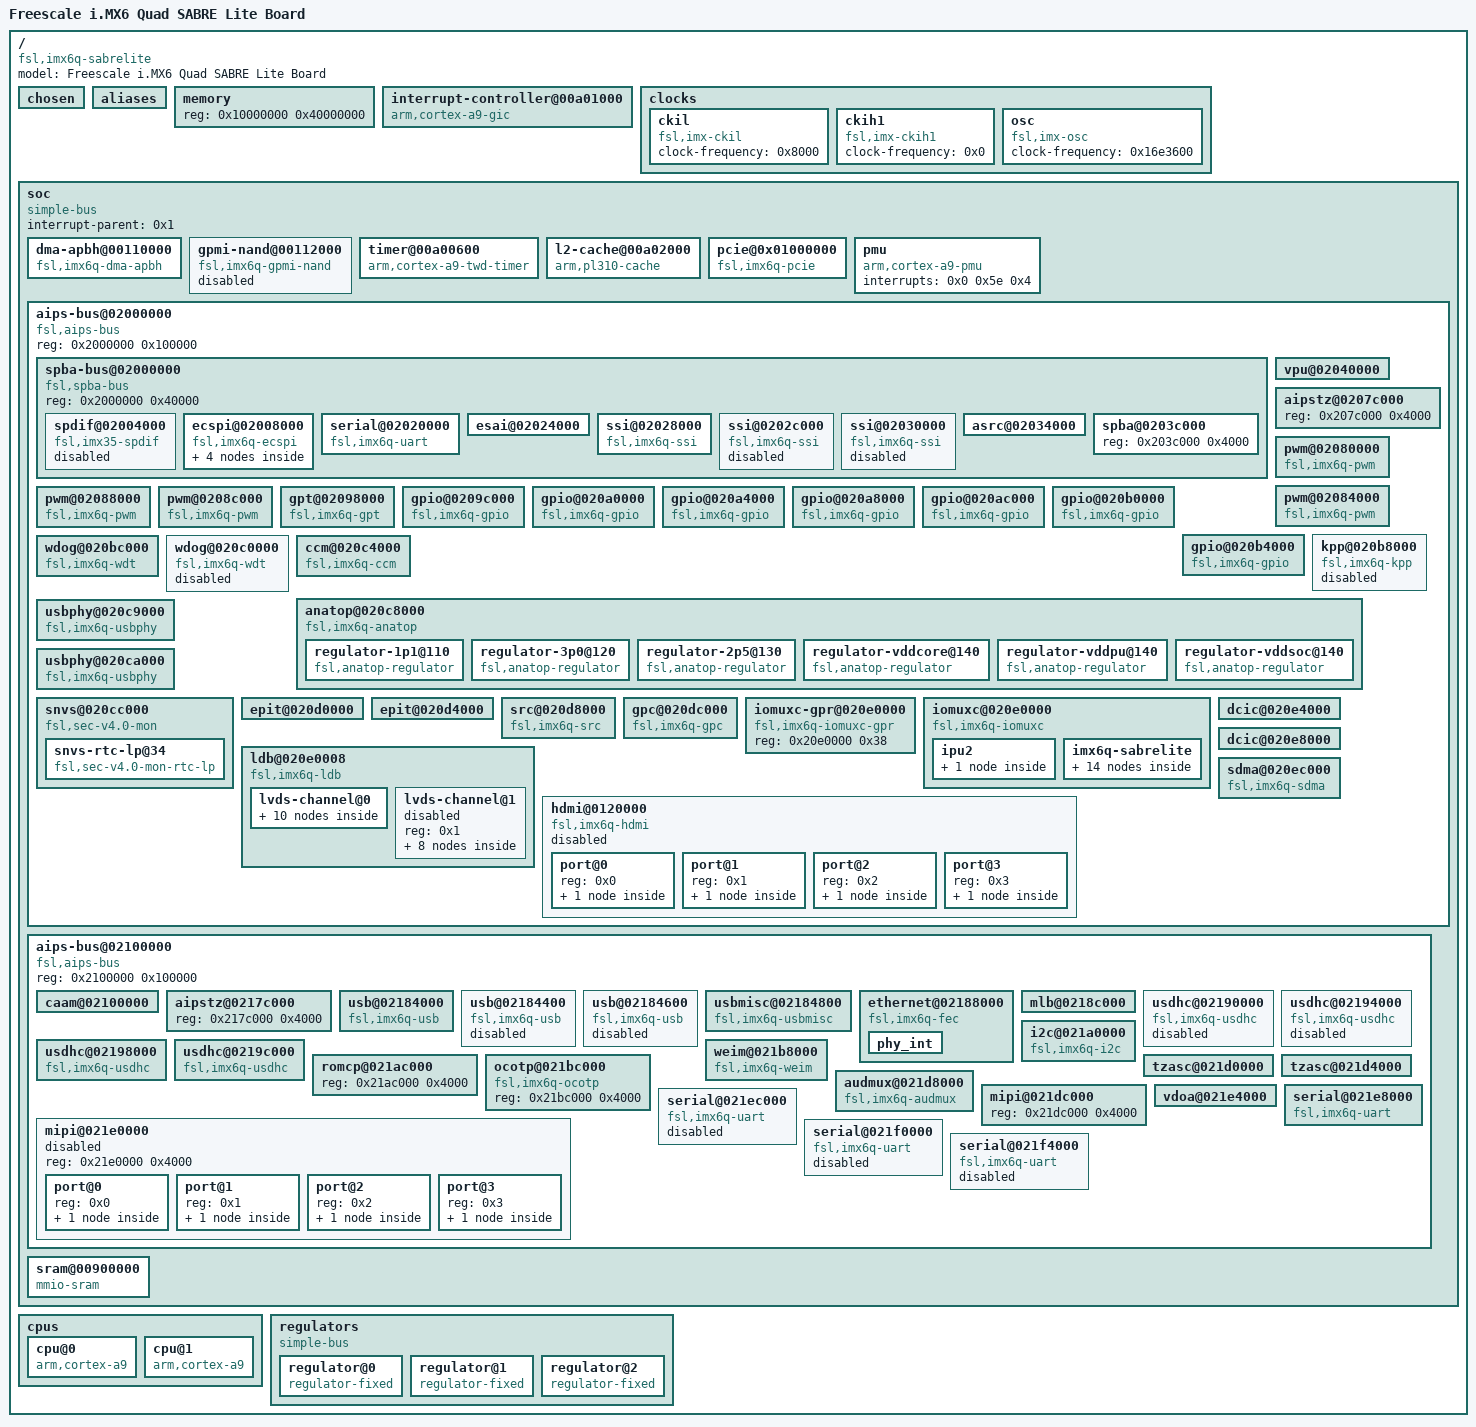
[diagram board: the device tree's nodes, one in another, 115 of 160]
/dts-v1/;

/ {
	#address-cells = <0x1>;
	#size-cells = <0x1>;
	model = "Freescale i.MX6 Quad SABRE Lite Board";
	compatible = "fsl,imx6q-sabrelite", "fsl,imx6q";

	chosen {
		stdout-path = "/soc/aips-bus@02100000/serial@021e8000";
bootargs = "console=ttymxc1,115200 root=/dev/mmcblk0 rw rootwait earlyprintk loglevel=8 mem=862M ip=dhcp video=mxcfb0:dev=ldb,LDB-XGA,if=RGB666";
	};

	aliases {
		ethernet0 = "/soc/aips-bus@02100000/ethernet@02188000";
		can0 = "/soc/aips-bus@02000000/flexcan@02090000";
		can1 = "/soc/aips-bus@02000000/flexcan@02094000";
		gpio0 = "/soc/aips-bus@02000000/gpio@0209c000";
		gpio1 = "/soc/aips-bus@02000000/gpio@020a0000";
		gpio2 = "/soc/aips-bus@02000000/gpio@020a4000";
		gpio3 = "/soc/aips-bus@02000000/gpio@020a8000";
		gpio4 = "/soc/aips-bus@02000000/gpio@020ac000";
		gpio5 = "/soc/aips-bus@02000000/gpio@020b0000";
		gpio6 = "/soc/aips-bus@02000000/gpio@020b4000";
		i2c0 = "/soc/aips-bus@02100000/i2c@021a0000";
		mmc0 = "/soc/aips-bus@02100000/usdhc@02190000";
		mmc1 = "/soc/aips-bus@02100000/usdhc@02194000";
		mmc2 = "/soc/aips-bus@02100000/usdhc@02198000";
		mmc3 = "/soc/aips-bus@02100000/usdhc@0219c000";
		serial0 = "/soc/aips-bus@02000000/spba-bus@02000000/serial@02020000";
		serial1 = "/soc/aips-bus@02100000/serial@021e8000";
		serial2 = "/soc/aips-bus@02100000/serial@021ec000";
		serial3 = "/soc/aips-bus@02100000/serial@021f0000";
		serial4 = "/soc/aips-bus@02100000/serial@021f4000";

		spi0 = "/soc/aips-bus@02000000/spba-bus@02000000/ecspi@02008000";
//		spi1 = "/soc/aips-bus@02000000/spba-bus@02000000/ecspi@0200c000";
//		spi2 = "/soc/aips-bus@02000000/spba-bus@02000000/ecspi@02010000";
//		spi3 = "/soc/aips-bus@02000000/spba-bus@02000000/ecspi@02014000";
//              spi4 = "/soc/aips-bus@02000000/spba-bus@02000000/ecspi@02018000";

		usbphy0 = "/soc/aips-bus@02000000/usbphy@020c9000";
		usbphy1 = "/soc/aips-bus@02000000/usbphy@020ca000";

	};

	memory {
		device_type = "memory";
		reg = <0x10000000 0x40000000>;
	};

	interrupt-controller@00a01000 {
		compatible = "arm,cortex-a9-gic";
		#interrupt-cells = <0x3>;
		interrupt-controller;
		reg = <0xa01000 0x1000 0xa00100 0x100>;
		linux,phandle = <0x1>;
		phandle = <0x1>;
	};

	clocks {
		#address-cells = <0x1>;
		#size-cells = <0x0>;

		ckil {
			compatible = "fsl,imx-ckil", "fixed-clock";
			#clock-cells = <0x0>;
			clock-frequency = <0x8000>;
		};

		ckih1 {
			compatible = "fsl,imx-ckih1", "fixed-clock";
			#clock-cells = <0x0>;
			clock-frequency = <0x0>;
		};

		osc {
			compatible = "fsl,imx-osc", "fixed-clock";
			#clock-cells = <0x0>;
			clock-frequency = <0x16e3600>;
		};
	};

	soc {
		#address-cells = <0x1>;
		#size-cells = <0x1>;
		compatible = "simple-bus";
		interrupt-parent = <0x1>;
		ranges;

		dma-apbh@00110000 {
			compatible = "fsl,imx6q-dma-apbh", "fsl,imx28-dma-apbh";
			reg = <0x110000 0x2000>;
			interrupts = <0x0 0xd 0x4 0x0 0xd 0x4 0x0 0xd 0x4 0x0 0xd 0x4>;
			interrupt-names = "gpmi0", "gpmi1", "gpmi2", "gpmi3";
			#dma-cells = <0x1>;
			dma-channels = <0x4>;
			clocks = <0x2 0x6a>;
			linux,phandle = <0x3>;
			phandle = <0x3>;
		};

		gpmi-nand@00112000 {
			compatible = "fsl,imx6q-gpmi-nand";
			#address-cells = <0x1>;
			#size-cells = <0x1>;
			reg = <0x112000 0x2000 0x114000 0x2000>;
			reg-names = "gpmi-nand", "bch";
			interrupts = <0x0 0xf 0x4>;
			interrupt-names = "bch";
			clocks = <0x2 0x98 0x2 0x99 0x2 0x97 0x2 0x96 0x2 0x95>;
			clock-names = "gpmi_io", "gpmi_apb", "gpmi_bch", "gpmi_bch_apb", "per1_bch";
			dmas = <0x3 0x0>;
			dma-names = "rx-tx";
			status = "disabled";
		};

		timer@00a00600 {
			compatible = "arm,cortex-a9-twd-timer";
			reg = <0xa00600 0x20>;
			interrupts = <0x1 0xd 0xf01>;
			clocks = <0x2 0xf>;
		};

		l2-cache@00a02000 {
			compatible = "arm,pl310-cache";
			reg = <0xa02000 0x1000>;
			interrupts = <0x0 0x5c 0x4>;
			cache-unified;
			cache-level = <0x2>;
			arm,tag-latency = <0x4 0x2 0x3>;
			arm,data-latency = <0x4 0x2 0x3>;
			linux,phandle = <0x3f>;
			phandle = <0x3f>;
		};

		pcie@0x01000000 {
			compatible = "fsl,imx6q-pcie", "snps,dw-pcie";
			reg = <0x1ffc000 0x4000>;
			#address-cells = <0x3>;
			#size-cells = <0x2>;
			device_type = "pci";
			ranges = <0x800 0x0 0x1f00000 0x1f00000 0x0 0x80000 0x81000000 0x0 0x0 0x1f80000 0x0 0x10000 0x82000000 0x0 0x1000000 0x1000000 0x0 0xf00000>;
			num-lanes = <0x1>;
			interrupts = <0x0 0x78 0x4>;
			interrupt-names = "msi";
			#interrupt-cells = <0x1>;
			interrupt-map-mask = <0x0 0x0 0x0 0x7>;
			interrupt-map = <0x0 0x0 0x0 0x1 0x1 0x0 0x7b 0x4 0x0 0x0 0x0 0x2 0x1 0x0 0x7a 0x4 0x0 0x0 0x0 0x3 0x1 0x0 0x79 0x4 0x0 0x0 0x0 0x4 0x1 0x0 0x78 0x4>;
			clocks = <0x2 0x90 0x2 0xce 0x2 0xbd>;
			clock-names = "pcie", "pcie_bus", "pcie_phy";
			status = "okay";
		};

		pmu {
			compatible = "arm,cortex-a9-pmu";
			interrupts = <0x0 0x5e 0x4>;
		};

		aips-bus@02000000 {
			compatible = "fsl,aips-bus", "simple-bus";
			#address-cells = <0x1>;
			#size-cells = <0x1>;
			reg = <0x2000000 0x100000>;
			ranges;

			spba-bus@02000000 {
				compatible = "fsl,spba-bus", "simple-bus";
				#address-cells = <0x1>;
				#size-cells = <0x1>;
				reg = <0x2000000 0x40000>;
				ranges;

				spdif@02004000 {
					compatible = "fsl,imx35-spdif";
					reg = <0x2004000 0x4000>;
					interrupts = <0x0 0x34 0x4>;
					dmas = <0x4 0xe 0x12 0x0 0x4 0xf 0x12 0x0>;
					dma-names = "rx", "tx";
					clocks = <0x2 0xc5 0x2 0x3 0x2 0xc5 0x2 0x0 0x2 0x0 0x2 0x0 0x2 0x0 0x2 0x0 0x2 0x0>;
					clock-names = "core", "rxtx0", "rxtx1", "rxtx2", "rxtx3", "rxtx4", "rxtx5", "rxtx6", "rxtx7";
					status = "disabled";
				};

				ecspi@02008000 {
					#address-cells = <0x1>;
					#size-cells = <0x0>;
					compatible = "fsl,imx6q-ecspi", "fsl,imx51-ecspi";
					reg = <0x2008000 0x4000>;
					interrupts = <0x0 0x1f 0x4>;
					clocks = <0x2 0x70 0x2 0x70>;
					clock-names = "ipg", "per";
					dmas = <0x4 0x3 0x7 0x1 0x4 0x4 0x7 0x2>;
					dma-names = "rx", "tx";
					status = "okay";
					fsl,spi-num-chipselects = <0x4>;
//					pinctrl-names = "default";
//					pinctrl-0 = <0x6>;

				        spidev@0x00 {
   					        compatible = "spidev";
					        spi-max-frequency = <20000000>;
					        reg = <0>;
    					};
				        spidev@0x01 {
   					        compatible = "spidev";
					        spi-max-frequency = <20000000>;
					        reg = <1>;
    					};
				        spidev@0x02 {
   					        compatible = "spidev";
					        spi-max-frequency = <20000000>;
					        reg = <2>;
    					};
				        spidev@0x03 {
   					        compatible = "spidev";
					        spi-max-frequency = <20000000>;
					        reg = <3>;
    					};

				};
/*
				ecspi@0200c000 {
					#address-cells = <0x1>;
					#size-cells = <0x0>;
					compatible = "fsl,imx6q-ecspi", "fsl,imx51-ecspi";
					reg = <0x200c000 0x4000>;
					interrupts = <0x0 0x20 0x4>;
					clocks = <0x2 0x71 0x2 0x71>;
					clock-names = "ipg", "per";
					dmas = <0x4 0x5 0x7 0x1 0x4 0x6 0x7 0x2>;
					dma-names = "rx", "tx";
					status = "disabled";
				};
				ecspi@02010000 {
					#address-cells = <0x1>;
					#size-cells = <0x0>;
					compatible = "fsl,imx6q-ecspi", "fsl,imx51-ecspi";
					reg = <0x2010000 0x4000>;
					interrupts = <0x0 0x21 0x4>;
					clocks = <0x2 0x72 0x2 0x72>;
					clock-names = "ipg", "per";
					dmas = <0x4 0x7 0x7 0x1 0x4 0x8 0x7 0x2>;
					dma-names = "rx", "tx";
					status = "disabled";
				};

				ecspi@02014000 {
					#address-cells = <0x1>;
					#size-cells = <0x0>;
					compatible = "fsl,imx6q-ecspi", "fsl,imx51-ecspi";
					reg = <0x2014000 0x4000>;
					interrupts = <0x0 0x22 0x4>;
					clocks = <0x2 0x73 0x2 0x73>;
					clock-names = "ipg", "per";
					dmas = <0x4 0x9 0x7 0x1 0x4 0xa 0x7 0x2>;
					dma-names = "rx", "tx";
					status = "disabled";
				};
*/
				serial@02020000 {
					compatible = "fsl,imx6q-uart", "fsl,imx21-uart";
					reg = <0x2020000 0x4000>;
					interrupts = <0x0 0x1a 0x4>;
					clocks = <0x2 0xa0 0x2 0xa1>;
					clock-names = "ipg", "per";
					dmas = <0x4 0x19 0x4 0x0 0x4 0x1a 0x4 0x0>;
					dma-names = "rx", "tx";
					status = "okay";
					pinctrl-names = "default";
					pinctrl-0 = <0x7>;
				};

				esai@02024000 {
					reg = <0x2024000 0x4000>;
					interrupts = <0x0 0x33 0x4>;
				};

				ssi@02028000 {
					compatible = "fsl,imx6q-ssi", "fsl,imx51-ssi";
					reg = <0x2028000 0x4000>;
					interrupts = <0x0 0x2e 0x4>;
					clocks = <0x2 0xb2>;
					dmas = <0x4 0x25 0x1 0x0 0x4 0x26 0x1 0x0>;
					dma-names = "rx", "tx";
					fsl,fifo-depth = <0xf>;
					status = "okay";
					linux,phandle = <0x49>;
					phandle = <0x49>;
				};

				ssi@0202c000 {
					compatible = "fsl,imx6q-ssi", "fsl,imx51-ssi";
					reg = <0x202c000 0x4000>;
					interrupts = <0x0 0x2f 0x4>;
					clocks = <0x2 0xb3>;
					dmas = <0x4 0x29 0x1 0x0 0x4 0x2a 0x1 0x0>;
					dma-names = "rx", "tx";
					fsl,fifo-depth = <0xf>;
					status = "disabled";
				};

				ssi@02030000 {
					compatible = "fsl,imx6q-ssi", "fsl,imx51-ssi";
					reg = <0x2030000 0x4000>;
					interrupts = <0x0 0x30 0x4>;
					clocks = <0x2 0xb4>;
					dmas = <0x4 0x2d 0x1 0x0 0x4 0x2e 0x1 0x0>;
					dma-names = "rx", "tx";
					fsl,fifo-depth = <0xf>;
					status = "disabled";
				};

				asrc@02034000 {
					reg = <0x2034000 0x4000>;
					interrupts = <0x0 0x32 0x4>;
				};

				spba@0203c000 {
					reg = <0x203c000 0x4000>;
				};
/*
				ecspi@02018000 {
					#address-cells = <0x1>;
					#size-cells = <0x0>;
					compatible = "fsl,imx6q-ecspi", "fsl,imx51-ecspi";
					reg = <0x2018000 0x4000>;
					interrupts = <0x0 0x23 0x4>;
					clocks = <0x2 0x74 0x2 0x74>;
					clock-names = "ipg", "per";
					status = "disabled";
				};
*/
			};

			vpu@02040000 {
				reg = <0x2040000 0x3c000>;
				interrupts = <0x0 0x3 0x4 0x0 0xc 0x4>;
			};

			aipstz@0207c000 {
				reg = <0x207c000 0x4000>;
			};

			pwm@02080000 {
				#pwm-cells = <0x2>;
				compatible = "fsl,imx6q-pwm", "fsl,imx27-pwm";
				reg = <0x2080000 0x4000>;
				interrupts = <0x0 0x53 0x4>;
				clocks = <0x2 0x3e 0x2 0x91>;
				clock-names = "ipg", "per";
				pinctrl-names = "default";
				pinctrl-0 = <0x8>;
				status = "okay";
				linux,phandle = <0x4b>;
				phandle = <0x4b>;
			};

			pwm@02084000 {
				#pwm-cells = <0x2>;
				compatible = "fsl,imx6q-pwm", "fsl,imx27-pwm";
				reg = <0x2084000 0x4000>;
				interrupts = <0x0 0x54 0x4>;
				clocks = <0x2 0x3e 0x2 0x92>;
				clock-names = "ipg", "per";
			};

			pwm@02088000 {
				#pwm-cells = <0x2>;
				compatible = "fsl,imx6q-pwm", "fsl,imx27-pwm";
				reg = <0x2088000 0x4000>;
				interrupts = <0x0 0x55 0x4>;
				clocks = <0x2 0x3e 0x2 0x93>;
				clock-names = "ipg", "per";
				pinctrl-names = "default";
				pinctrl-0 = <0x9>;
				status = "okay";
			};

			pwm@0208c000 {
				#pwm-cells = <0x2>;
				compatible = "fsl,imx6q-pwm", "fsl,imx27-pwm";
				reg = <0x208c000 0x4000>;
				interrupts = <0x0 0x56 0x4>;
				clocks = <0x2 0x3e 0x2 0x94>;
				clock-names = "ipg", "per";
				pinctrl-names = "default";
				pinctrl-0 = <0xa>;
				status = "okay";
				linux,phandle = <0x4c>;
				phandle = <0x4c>;
			};
/*
			flexcan@02090000 {
				compatible = "fsl,imx6q-flexcan";
				reg = <0x2090000 0x4000>;
				interrupts = <0x0 0x6e 0x4>;
				clocks = <0x2 0x6c 0x2 0x6d>;
				clock-names = "ipg", "per";
				status = "disabled";
			};

			flexcan@02094000 {
				compatible = "fsl,imx6q-flexcan";
				reg = <0x2094000 0x4000>;
				interrupts = <0x0 0x6f 0x4>;
				clocks = <0x2 0x6e 0x2 0x6f>;
				clock-names = "ipg", "per";
				status = "disabled";
			};
*/
			gpt@02098000 {
				compatible = "fsl,imx6q-gpt", "fsl,imx31-gpt";
				reg = <0x2098000 0x4000>;
				interrupts = <0x0 0x37 0x4>;
				clocks = <0x2 0x77 0x2 0x78>;
				clock-names = "ipg", "per";
			};

			gpio@0209c000 {
				compatible = "fsl,imx6q-gpio", "fsl,imx35-gpio";
				reg = <0x209c000 0x4000>;
				interrupts = <0x0 0x42 0x4 0x0 0x43 0x4>;
				gpio-controller;
				#gpio-cells = <0x2>;
				interrupt-controller;
				#interrupt-cells = <0x2>;
				linux,phandle = <0x21>;
				phandle = <0x21>;
			};

			gpio@020a0000 {
				compatible = "fsl,imx6q-gpio", "fsl,imx35-gpio";
				reg = <0x20a0000 0x4000>;
				interrupts = <0x0 0x44 0x4 0x0 0x45 0x4>;
				gpio-controller;
				#gpio-cells = <0x2>;
				interrupt-controller;
				#interrupt-cells = <0x2>;
				linux,phandle = <0x27>;
				phandle = <0x27>;
			};

			gpio@020a4000 {
				compatible = "fsl,imx6q-gpio", "fsl,imx35-gpio";
				reg = <0x20a4000 0x4000>;
				interrupts = <0x0 0x46 0x4 0x0 0x47 0x4>;
				gpio-controller;
				#gpio-cells = <0x2>;
				interrupt-controller;
				#interrupt-cells = <0x2>;
				linux,phandle = <0x5>;
				phandle = <0x5>;
			};

			gpio@020a8000 {
				compatible = "fsl,imx6q-gpio", "fsl,imx35-gpio";
				reg = <0x20a8000 0x4000>;
				interrupts = <0x0 0x48 0x4 0x0 0x49 0x4>;
				gpio-controller;
				#gpio-cells = <0x2>;
				interrupt-controller;
				#interrupt-cells = <0x2>;
				linux,phandle = <0x48>;
				phandle = <0x48>;
			};

			gpio@020ac000 {
				compatible = "fsl,imx6q-gpio", "fsl,imx35-gpio";
				reg = <0x20ac000 0x4000>;
				interrupts = <0x0 0x4a 0x4 0x0 0x4b 0x4>;
				gpio-controller;
				#gpio-cells = <0x2>;
				interrupt-controller;
				#interrupt-cells = <0x2>;
			};

			gpio@020b0000 {
				compatible = "fsl,imx6q-gpio", "fsl,imx35-gpio";
				reg = <0x20b0000 0x4000>;
				interrupts = <0x0 0x4c 0x4 0x0 0x4d 0x4>;
				gpio-controller;
				#gpio-cells = <0x2>;
				interrupt-controller;
				#interrupt-cells = <0x2>;
			};

			gpio@020b4000 {
				compatible = "fsl,imx6q-gpio", "fsl,imx35-gpio";
				reg = <0x20b4000 0x4000>;
				interrupts = <0x0 0x4e 0x4 0x0 0x4f 0x4>;
				gpio-controller;
				#gpio-cells = <0x2>;
				interrupt-controller;
				#interrupt-cells = <0x2>;
				linux,phandle = <0x24>;
				phandle = <0x24>;
			};

			kpp@020b8000 {
				compatible = "fsl,imx6q-kpp", "fsl,imx21-kpp";
				reg = <0x20b8000 0x4000>;
				interrupts = <0x0 0x52 0x4>;
				clocks = <0x2 0x3e>;
				status = "disabled";
			};

			wdog@020bc000 {
				compatible = "fsl,imx6q-wdt", "fsl,imx21-wdt";
				reg = <0x20bc000 0x4000>;
				interrupts = <0x0 0x50 0x4>;
				clocks = <0x2 0x0>;
			};

			wdog@020c0000 {
				compatible = "fsl,imx6q-wdt", "fsl,imx21-wdt";
				reg = <0x20c0000 0x4000>;
				interrupts = <0x0 0x51 0x4>;
				clocks = <0x2 0x0>;
				status = "disabled";
			};

			ccm@020c4000 {
				compatible = "fsl,imx6q-ccm";
				reg = <0x20c4000 0x4000>;
				interrupts = <0x0 0x57 0x4 0x0 0x58 0x4>;
				#clock-cells = <0x1>;
				linux,phandle = <0x2>;
				phandle = <0x2>;
			};


			anatop@020c8000 {
				compatible = "fsl,imx6q-anatop", "syscon", "simple-bus";
				reg = <0x20c8000 0x1000>;
				interrupts = <0x0 0x31 0x4 0x0 0x36 0x4 0x0 0x7f 0x4>;
				linux,phandle = <0xb>;
				phandle = <0xb>;

				regulator-1p1@110 {
					compatible = "fsl,anatop-regulator";
					regulator-name = "vdd1p1";
					regulator-min-microvolt = <0xc3500>;
					regulator-max-microvolt = <0x14fb18>;
					regulator-always-on;
					anatop-reg-offset = <0x110>;
					anatop-vol-bit-shift = <0x8>;
					anatop-vol-bit-width = <0x5>;
					anatop-min-bit-val = <0x4>;
					anatop-min-voltage = <0xc3500>;
					anatop-max-voltage = <0x14fb18>;
				};

				regulator-3p0@120 {
					compatible = "fsl,anatop-regulator";
					regulator-name = "vdd3p0";
					regulator-min-microvolt = <0x2ab980>;
					regulator-max-microvolt = <0x3010b0>;
					regulator-always-on;
					anatop-reg-offset = <0x120>;
					anatop-vol-bit-shift = <0x8>;
					anatop-vol-bit-width = <0x5>;
					anatop-min-bit-val = <0x0>;
					anatop-min-voltage = <0x280de8>;
					anatop-max-voltage = <0x33e140>;
				};

				regulator-2p5@130 {
					compatible = "fsl,anatop-regulator";
					regulator-name = "vdd2p5";
					regulator-min-microvolt = <0x1e8480>;
					regulator-max-microvolt = <0x29f630>;
					regulator-always-on;
					anatop-reg-offset = <0x130>;
					anatop-vol-bit-shift = <0x8>;
					anatop-vol-bit-width = <0x5>;
					anatop-min-bit-val = <0x0>;
					anatop-min-voltage = <0x1e8480>;
					anatop-max-voltage = <0x29f630>;
				};

				regulator-vddcore@140 {
					compatible = "fsl,anatop-regulator";
					regulator-name = "vddarm";
					regulator-min-microvolt = <0xb1008>;
					regulator-max-microvolt = <0x162010>;
					regulator-always-on;
					anatop-reg-offset = <0x140>;
					anatop-vol-bit-shift = <0x0>;
					anatop-vol-bit-width = <0x5>;
					anatop-delay-reg-offset = <0x170>;
					anatop-delay-bit-shift = <0x18>;
					anatop-delay-bit-width = <0x2>;
					anatop-min-bit-val = <0x1>;
					anatop-min-voltage = <0xb1008>;
					anatop-max-voltage = <0x162010>;
					linux,phandle = <0x40>;
					phandle = <0x40>;
				};

				regulator-vddpu@140 {
					compatible = "fsl,anatop-regulator";
					regulator-name = "vddpu";
					regulator-min-microvolt = <0xb1008>;
					regulator-max-microvolt = <0x162010>;
					regulator-always-on;
					anatop-reg-offset = <0x140>;
					anatop-vol-bit-shift = <0x9>;
					anatop-vol-bit-width = <0x5>;
					anatop-delay-reg-offset = <0x170>;
					anatop-delay-bit-shift = <0x1a>;
					anatop-delay-bit-width = <0x2>;
					anatop-min-bit-val = <0x1>;
					anatop-min-voltage = <0xb1008>;
					anatop-max-voltage = <0x162010>;
					linux,phandle = <0x41>;
					phandle = <0x41>;
				};

				regulator-vddsoc@140 {
					compatible = "fsl,anatop-regulator";
					regulator-name = "vddsoc";
					regulator-min-microvolt = <0xb1008>;
					regulator-max-microvolt = <0x162010>;
					regulator-always-on;
					anatop-reg-offset = <0x140>;
					anatop-vol-bit-shift = <0x12>;
					anatop-vol-bit-width = <0x5>;
					anatop-delay-reg-offset = <0x170>;
					anatop-delay-bit-shift = <0x1c>;
					anatop-delay-bit-width = <0x2>;
					anatop-min-bit-val = <0x1>;
					anatop-min-voltage = <0xb1008>;
					anatop-max-voltage = <0x162010>;
					linux,phandle = <0x42>;
					phandle = <0x42>;
				};
			};

/*
			tempmon {
				compatible = "fsl,imx6q-tempmon";
				interrupts = <0x0 0x31 0x4>;
				fsl,tempmon = <0xb>;
				fsl,tempmon-data = <0xc>;
				clocks = <0x2 0xac>;
			};
*/
			usbphy@020c9000 {
				compatible = "fsl,imx6q-usbphy", "fsl,imx23-usbphy";
				reg = <0x20c9000 0x1000>;
				interrupts = <0x0 0x2c 0x4>;
				clocks = <0x2 0xb6>;
				fsl,anatop = <0xb>;
				linux,phandle = <0x1c>;
				phandle = <0x1c>;
			};

			usbphy@020ca000 {
				compatible = "fsl,imx6q-usbphy", "fsl,imx23-usbphy";
				reg = <0x20ca000 0x1000>;
				interrupts = <0x0 0x2d 0x4>;
				clocks = <0x2 0xb7>;
				fsl,anatop = <0xb>;
				linux,phandle = <0x20>;
				phandle = <0x20>;
			};

			snvs@020cc000 {
				compatible = "fsl,sec-v4.0-mon", "simple-bus";
				#address-cells = <0x1>;
				#size-cells = <0x1>;
				ranges = <0x0 0x20cc000 0x4000>;

				snvs-rtc-lp@34 {
					compatible = "fsl,sec-v4.0-mon-rtc-lp";
					reg = <0x34 0x58>;
					interrupts = <0x0 0x13 0x4 0x0 0x14 0x4>;
				};
			};

			epit@020d0000 {
				reg = <0x20d0000 0x4000>;
				interrupts = <0x0 0x38 0x4>;
			};

			epit@020d4000 {
				reg = <0x20d4000 0x4000>;
				interrupts = <0x0 0x39 0x4>;
			};

			src@020d8000 {
				compatible = "fsl,imx6q-src", "fsl,imx51-src";
				reg = <0x20d8000 0x4000>;
				interrupts = <0x0 0x5b 0x4 0x0 0x60 0x4>;
				#reset-cells = <0x1>;
				linux,phandle = <0x30>;
				phandle = <0x30>;
			};

			gpc@020dc000 {
				compatible = "fsl,imx6q-gpc";
				reg = <0x20dc000 0x4000>;
				interrupts = <0x0 0x59 0x4 0x0 0x5a 0x4>;
			};

			iomuxc-gpr@020e0000 {
				compatible = "fsl,imx6q-iomuxc-gpr", "syscon";
				reg = <0x20e0000 0x38>;
				linux,phandle = <0xe>;
				phandle = <0xe>;
			};

			iomuxc@020e0000 {
				compatible = "fsl,imx6q-iomuxc";
				reg = <0x20e0000 0x4000>;
				pinctrl-names = "default";
				pinctrl-0 = <0xd>;

				ipu2 {

					ipu2grp-1 {
						fsl,pins = <0x15c 0x470 0x0 0x1 0x0 0x10 0x160 0x474 0x0 0x1 0x0 0x10 0x164 0x478 0x0 0x1 0x0 0x10 0x168 0x47c 0x0 0x1 0x0 0x10 0x16c 0x480 0x0 0x1 0x0 0x80000000 0x170 0x484 0x0 0x1 0x0 0x10 0x174 0x488 0x0 0x1 0x0 0x10 0x178 0x48c 0x0 0x1 0x0 0x10 0x17c 0x490 0x0 0x1 0x0 0x10 0x180 0x494 0x0 0x1 0x0 0x10 0x184 0x498 0x0 0x1 0x0 0x10 0x188 0x49c 0x0 0x1 0x0 0x10 0x18c 0x4a0 0x0 0x1 0x0 0x10 0x190 0x4a4 0x0 0x1 0x0 0x10 0x194 0x4a8 0x0 0x1 0x0 0x10 0x198 0x4ac 0x0 0x1 0x0 0x10 0x19c 0x4b0 0x0 0x1 0x0 0x10 0x1a0 0x4b4 0x0 0x1 0x0 0x10 0x1a4 0x4b8 0x0 0x1 0x0 0x10 0x1a8 0x4bc 0x0 0x1 0x0 0x10 0x1ac 0x4c0 0x0 0x1 0x0 0x10 0x1b0 0x4c4 0x0 0x1 0x0 0x10 0x1b4 0x4c8 0x0 0x1 0x0 0x10 0x1b8 0x4cc 0x0 0x1 0x0 0x10 0x1bc 0x4d0 0x0 0x1 0x0 0x10 0x1c0 0x4d4 0x0 0x1 0x0 0x10 0x1c4 0x4d8 0x0 0x1 0x0 0x10 0x1c8 0x4dc 0x0 0x1 0x0 0x10 0x1cc 0x4e0 0x0 0x1 0x0 0x10>;
					};
				};

				imx6q-sabrelite {

					hoggrp {
						fsl,pins = <0x220 0x5f0 0x0 0x0 0x0 0x30b0>;
						linux,phandle = <0xd>;
						phandle = <0xd>;
					};

					audmuxgrp {
						fsl,pins = <0x54 0x368 0x7b4 0x3 0x0 0x130b0 0x35c 0x744 0x7c4 0x3 0x1 0x130b0 0x50 0x364 0x7b8 0x3 0x0 0x110b0 0x4c 0x360 0x7c8 0x3 0x0 0x130b0>;
						linux,phandle = <0x2a>;
						phandle = <0x2a>;
					};

					ecspi1grp {
						fsl,pins = <0x94 0x3a8 0x7f8 0x1 0x0 0x100b1 0x98 0x3ac 0x7fc 0x1 0x0 0x100b1 0x90 0x3a4 0x7f4 0x1 0x0 0x100b1 0x9c 0x3b0 0x0 0x5 0x0 0xb1>;
						linux,phandle = <0x6>;
						phandle = <0x6>;
					};

					enetgrp {
						fsl,pins = <0x1d0 0x4e4 0x840 0x1 0x0 0x100b0 0x1f4 0x508 0x0 0x1 0x0 0x100b0 0x58 0x36c 0x0 0x1 0x0 0x100b0 0x5c 0x370 0x0 0x1 0x0 0x100b0 0x60 0x374 0x0 0x1 0x0 0x100b0 0x64 0x378 0x0 0x1 0x0 0x100b0 0x68 0x37c 0x0 0x1 0x0 0x100b0 0x74 0x388 0x0 0x1 0x0 0x100b0 0x1d4 0x4e8 0x0 0x1 0x0 0x100b0 0x84 0x398 0x844 0x1 0x0 0x1b0b0 0x70 0x384 0x848 0x1 0x0 0x1b0b0 0x78 0x38c 0x84c 0x1 0x0 0x1b0b0 0x7c 0x390 0x850 0x1 0x0 0x1b0b0 0x80 0x394 0x854 0x1 0x0 0x1b0b0 0x6c 0x380 0x858 0x1 0x0 0x1b0b0 0xac 0x3c0 0x0 0x5 0x0 0xb0 0x230 0x600 0x3c 0x11 0xff000609 0xb1>;
						linux,phandle = <0x22>;
						phandle = <0x22>;
					};

					gpio_keysgrp {
						fsl,pins = <0x308 0x6f0 0x0 0x5 0x0 0x1b0b0 0x300 0x6e8 0x0 0x5 0x0 0x1b0b0 0x30c 0x6f4 0x0 0x5 0x0 0x1b0b0 0x304 0x6ec 0x0 0x5 0x0 0x1b0b0 0x250 0x620 0x0 0x5 0x0 0x1b0b0 0x254 0x624 0x0 0x5 0x0 0x1b0b0>;
						linux,phandle = <0x47>;
						phandle = <0x47>;
					};

					i2c1grp {
						fsl,pins = <0xa4 0x3b8 0x898 0x6 0x0 0x4001b8b1 0xc4 0x3d8 0x89c 0x1 0x0 0x4001b8b1>;
						linux,phandle = <0x28>;
						phandle = <0x28>;
					};

					pwm1grp {
						fsl,pins = <0x344 0x72c 0x0 0x3 0x0 0x1b0b1>;
						linux,phandle = <0x8>;
						phandle = <0x8>;
					};

					pwm3grp {
						fsl,pins = <0x33c 0x724 0x0 0x2 0x0 0x1b0b1>;
						linux,phandle = <0x9>;
						phandle = <0x9>;
					};

					pwm4grp {
						fsl,pins = <0x348 0x730 0x0 0x2 0x0 0x1b0b1>;
						linux,phandle = <0xa>;
						phandle = <0xa>;
					};

					uart1grp {
						fsl,pins = <0x2a8 0x690 0x0 0x1 0x0 0x1b0b1 0x2ac 0x694 0x920 0x1 0x3 0x1b0b1>;
						linux,phandle = <0x7>;
						phandle = <0x7>;
					};

					uart2grp {
						fsl,pins = <0xbc 0x3d0 0x0 0x4 0x0 0x1b0b1 0xc0 0x3d4 0x928 0x4 0x1 0x1b0b1>;
						linux,phandle = <0x2f>;
						phandle = <0x2f>;
					};

					usbotggrp {
						fsl,pins = <0x224 0x5f4 0x4 0x3 0xff0d0101 0x17059 0x218 0x5e8 0x944 0x2 0x1 0x1b0b0 0xa8 0x3bc 0x0 0x5 0x0 0xb0>;
						linux,phandle = <0x1f>;
						phandle = <0x1f>;
					};

					usdhc3grp {
						fsl,pins = <0x2b8 0x6a0 0x0 0x0 0x0 0x17059 0x2bc 0x6a4 0x0 0x0 0x0 0x10059 0x2c0 0x6a8 0x0 0x0 0x0 0x17059 0x2c4 0x6ac 0x0 0x0 0x0 0x17059 0x2c8 0x6b0 0x0 0x0 0x0 0x17059 0x2cc 0x6b4 0x0 0x0 0x0 0x17059 0x2b0 0x698 0x0 0x5 0x0 0x1b0b0 0x2b4 0x69c 0x0 0x5 0x0 0x1f0b0>;
						linux,phandle = <0x23>;
						phandle = <0x23>;
					};

					usdhc4grp {
						fsl,pins = <0x2f4 0x6dc 0x0 0x0 0x0 0x17059 0x2f8 0x6e0 0x0 0x0 0x0 0x10059 0x31c 0x704 0x0 0x1 0x0 0x17059 0x320 0x708 0x0 0x1 0x0 0x17059 0x324 0x70c 0x0 0x1 0x0 0x17059 0x328 0x710 0x0 0x1 0x0 0x17059 0x314 0x6fc 0x0 0x5 0x0 0x1b0b0>;
						linux,phandle = <0x26>;
						phandle = <0x26>;
					};
				};
			};

			ldb@020e0008 {
				#address-cells = <0x1>;
				#size-cells = <0x0>;
				compatible = "fsl,imx6q-ldb", "fsl,imx53-ldb";
				gpr = <0xe>;
				status = "okay";
				clocks = <0x2 0x21 0x2 0x22 0x2 0x27 0x2 0x28 0x2 0x29 0x2 0x2a 0x2 0x87 0x2 0x88>;
				clock-names = "di0_pll", "di1_pll", "di0_sel", "di1_sel", "di2_sel", "di3_sel", "di0", "di1";

				lvds-channel@0 {
					#address-cells = <0x1>;
					#size-cells = <0x0>;
					reg = <0x0>;
					status = "okay";
					fsl,data-mapping = "spwg";
					fsl,data-width = <0x12>;

					port@0 {
						reg = <0x0>;

						endpoint {
							remote-endpoint = <0xf>;
							linux,phandle = <0x33>;
							phandle = <0x33>;
						};
					};

					port@1 {
						reg = <0x1>;

						endpoint {
							remote-endpoint = <0x10>;
							linux,phandle = <0x37>;
							phandle = <0x37>;
						};
					};

					port@2 {
						reg = <0x2>;

						endpoint {
							remote-endpoint = <0x11>;
							linux,phandle = <0x3a>;
							phandle = <0x3a>;
						};
					};

					port@3 {
						reg = <0x3>;

						endpoint {
							remote-endpoint = <0x12>;
							linux,phandle = <0x3d>;
							phandle = <0x3d>;
						};
					};

					display-timings {
						native-mode = <0x13>;

						hsd100pxn1 {
							clock-frequency = <0x3dfd240>;
							hactive = <0x400>;
							vactive = <0x300>;
							hback-porch = <0xdc>;
							hfront-porch = <0x28>;
							vback-porch = <0x15>;
							vfront-porch = <0x7>;
							hsync-len = <0x3c>;
							vsync-len = <0xa>;
							linux,phandle = <0x13>;
							phandle = <0x13>;
						};
					};
				};

				lvds-channel@1 {
					#address-cells = <0x1>;
					#size-cells = <0x0>;
					reg = <0x1>;
					status = "disabled";

					port@0 {
						reg = <0x0>;

						endpoint {
							remote-endpoint = <0x14>;
							linux,phandle = <0x34>;
							phandle = <0x34>;
						};
					};

					port@1 {
						reg = <0x1>;

						endpoint {
							remote-endpoint = <0x15>;
							linux,phandle = <0x38>;
							phandle = <0x38>;
						};
					};

					port@2 {
						reg = <0x2>;

						endpoint {
							remote-endpoint = <0x16>;
							linux,phandle = <0x3b>;
							phandle = <0x3b>;
						};
					};

					port@3 {
						reg = <0x3>;

						endpoint {
							remote-endpoint = <0x17>;
							linux,phandle = <0x3e>;
							phandle = <0x3e>;
						};
					};
				};
			};

			hdmi@0120000 {
				#address-cells = <0x1>;
				#size-cells = <0x0>;
				reg = <0x120000 0x9000>;
				interrupts = <0x0 0x73 0x4>;
				gpr = <0xe>;
				clocks = <0x2 0x7b 0x2 0x7c>;
				clock-names = "iahb", "isfr";
				status = "disabled";
				compatible = "fsl,imx6q-hdmi";

				port@0 {
					reg = <0x0>;

					endpoint {
						remote-endpoint = <0x18>;
						linux,phandle = <0x31>;
						phandle = <0x31>;
					};
				};

				port@1 {
					reg = <0x1>;

					endpoint {
						remote-endpoint = <0x19>;
						linux,phandle = <0x35>;
						phandle = <0x35>;
					};
				};

				port@2 {
					reg = <0x2>;

					endpoint {
						remote-endpoint = <0x1a>;
						linux,phandle = <0x39>;
						phandle = <0x39>;
					};
				};

				port@3 {
					reg = <0x3>;

					endpoint {
						remote-endpoint = <0x1b>;
						linux,phandle = <0x3c>;
						phandle = <0x3c>;
					};
				};
			};

			dcic@020e4000 {
				reg = <0x20e4000 0x4000>;
				interrupts = <0x0 0x7c 0x4>;
			};

			dcic@020e8000 {
				reg = <0x20e8000 0x4000>;
				interrupts = <0x0 0x7d 0x4>;
			};

			sdma@020ec000 {
				compatible = "fsl,imx6q-sdma", "fsl,imx35-sdma";
				reg = <0x20ec000 0x4000>;
				interrupts = <0x0 0x2 0x4>;
				clocks = <0x2 0x9b 0x2 0x9b>;
				clock-names = "ipg", "ahb";
				#dma-cells = <0x3>;
//				fsl,sdma-ram-script-name = "imx/sdma/sdma-imx6q.bin";
				linux,phandle = <0x4>;
				phandle = <0x4>;
			};
		};

		aips-bus@02100000 {
			compatible = "fsl,aips-bus", "simple-bus";
			#address-cells = <0x1>;
			#size-cells = <0x1>;
			reg = <0x2100000 0x100000>;
			ranges;

			caam@02100000 {
				reg = <0x2100000 0x40000>;
				interrupts = <0x0 0x69 0x4 0x0 0x6a 0x4>;
			};

			aipstz@0217c000 {
				reg = <0x217c000 0x4000>;
			};

			usb@02184000 {
				compatible = "fsl,imx6q-usb", "fsl,imx27-usb";
				reg = <0x2184000 0x200>;
				interrupts = <0x0 0x2b 0x4>;
				clocks = <0x2 0xa2>;
				fsl,usbphy = <0x1c>;
				fsl,usbmisc = <0x1d 0x0>;
				status = "okay";
				vbus-supply = <0x1e>;
				pinctrl-names = "default";
				pinctrl-0 = <0x1f>;
				disable-over-current;
			};
/*
			usb@02184200 {
				compatible = "fsl,imx6q-usb", "fsl,imx27-usb";
				reg = <0x2184200 0x200>;
				interrupts = <0x0 0x28 0x4>;
				clocks = <0x2 0xa2>;
				fsl,usbphy = <0x20>;
				fsl,usbmisc = <0x1d 0x1>;
				status = "okay";
			};
*/
			usb@02184400 {
				compatible = "fsl,imx6q-usb", "fsl,imx27-usb";
				reg = <0x2184400 0x200>;
				interrupts = <0x0 0x29 0x4>;
				clocks = <0x2 0xa2>;
				fsl,usbmisc = <0x1d 0x2>;
				status = "disabled";
			};

			usb@02184600 {
				compatible = "fsl,imx6q-usb", "fsl,imx27-usb";
				reg = <0x2184600 0x200>;
				interrupts = <0x0 0x2a 0x4>;
				clocks = <0x2 0xa2>;
				fsl,usbmisc = <0x1d 0x3>;
				status = "disabled";
			};

			usbmisc@02184800 {
				#index-cells = <0x1>;
				compatible = "fsl,imx6q-usbmisc";
				reg = <0x2184800 0x200>;
				clocks = <0x2 0xa2>;
				linux,phandle = <0x1d>;
				phandle = <0x1d>;
			};

			ethernet@02188000 {
				compatible = "fsl,imx6q-fec";
				reg = <0x2188000 0x4000>;
				interrupts = <0x0 0x76 0x4 0x0 0x77 0x4>;
				clocks = <0x2 0x75 0x2 0x75 0x2 0xbe>;
				clock-names = "ipg", "ahb", "ptp";
				status = "okay";
				pinctrl-names = "default";
				pinctrl-0 = <0x19>;
				phy-mode = "mii";
				#address-cells = <0x0>;
				#size-cells = <0x1>;

				phy_int {
					reg = <0x6>;
					interrupt-parent = <0x1a>;
					interrupts = <0x1c 0x8>;
				};
			};

			mlb@0218c000 {
				reg = <0x218c000 0x4000>;
				interrupts = <0x0 0x35 0x4 0x0 0x75 0x4 0x0 0x7e 0x4>;
			};

			usdhc@02190000 {
				compatible = "fsl,imx6q-usdhc";
				reg = <0x2190000 0x4000>;
				interrupts = <0x0 0x16 0x4>;
				clocks = <0x2 0xa3 0x2 0xa3 0x2 0xa3>;
				clock-names = "ipg", "ahb", "per";
				bus-width = <0x4>;
				status = "disabled";
			};

			usdhc@02194000 {
				compatible = "fsl,imx6q-usdhc";
				reg = <0x2194000 0x4000>;
				interrupts = <0x0 0x17 0x4>;
				clocks = <0x2 0xa4 0x2 0xa4 0x2 0xa4>;
				clock-names = "ipg", "ahb", "per";
				bus-width = <0x4>;
				status = "disabled";
			};

			usdhc@02198000 {
				compatible = "fsl,imx6q-usdhc";
				reg = <0x2198000 0x4000>;
				interrupts = <0x0 0x18 0x4>;
				clocks = <0x2 0xa5 0x2 0xa5 0x2 0xa5>;
				clock-names = "ipg", "ahb", "per";
				bus-width = <0x4>;
				status = "okay";
				pinctrl-names = "default";
				pinctrl-0 = <0x23>;
				cd-gpios = <0x24 0x0 0x0>;
				wp-gpios = <0x24 0x1 0x0>;
				vmmc-supply = <0x25>;
			};

			usdhc@0219c000 {
				compatible = "fsl,imx6q-usdhc";
				reg = <0x219c000 0x4000>;
				interrupts = <0x0 0x19 0x4>;
				clocks = <0x2 0xa6 0x2 0xa6 0x2 0xa6>;
				clock-names = "ipg", "ahb", "per";
				bus-width = <0x4>;
				status = "okay";
				pinctrl-names = "default";
				pinctrl-0 = <0x26>;
				cd-gpios = <0x27 0x6 0x0>;
				vmmc-supply = <0x25>;
			};

			i2c@021a0000 {
				#address-cells = <0x1>;
				#size-cells = <0x0>;
				compatible = "fsl,imx6q-i2c", "fsl,imx21-i2c";
				reg = <0x21a0000 0x4000>;
				interrupts = <0x0 0x24 0x4>;
				clocks = <0x2 0x7d>;
				status = "okay";
				clock-frequency = <0x186a0>;
				pinctrl-names = "default";
				pinctrl-0 = <0x28>;
/*
                                 magnetometer: mag3110@0e {
                                         compatible = "fsl,mag3110";
                                         reg = <0x0e>;
                                 };
*/
			};

			romcp@021ac000 {
				reg = <0x21ac000 0x4000>;
			};
/*
			mmdc@021b0000 {
				compatible = "fsl,imx6q-mmdc";
				reg = <0x21b0000 0x4000>;
			};

			mmdc@021b4000 {
				reg = <0x21b4000 0x4000>;
			};
*/
			weim@021b8000 {
				compatible = "fsl,imx6q-weim";
				reg = <0x21b8000 0x4000>;
				interrupts = <0x0 0xe 0x4>;
				clocks = <0x2 0xc4>;
			};

			ocotp@021bc000 {
				compatible = "fsl,imx6q-ocotp", "syscon";
				reg = <0x21bc000 0x4000>;
				linux,phandle = <0xc>;
				phandle = <0xc>;
			};

			tzasc@021d0000 {
				reg = <0x21d0000 0x4000>;
				interrupts = <0x0 0x6c 0x4>;
			};

			tzasc@021d4000 {
				reg = <0x21d4000 0x4000>;
				interrupts = <0x0 0x6d 0x4>;
			};

			audmux@021d8000 {
				compatible = "fsl,imx6q-audmux", "fsl,imx31-audmux";
				reg = <0x21d8000 0x4000>;
				status = "okay";
				pinctrl-names = "default";
				pinctrl-0 = <0x2a>;
			};

			mipi@021dc000 {
				reg = <0x21dc000 0x4000>;
			};

			mipi@021e0000 {
				#address-cells = <0x1>;
				#size-cells = <0x0>;
				reg = <0x21e0000 0x4000>;
				status = "disabled";

				port@0 {
					reg = <0x0>;

					endpoint {
						remote-endpoint = <0x2b>;
						linux,phandle = <0x32>;
						phandle = <0x32>;
					};
				};

				port@1 {
					reg = <0x1>;

					endpoint {
						remote-endpoint = <0x2c>;
						linux,phandle = <0x36>;
						phandle = <0x36>;
					};
				};

				port@2 {
					reg = <0x2>;

					endpoint {
						remote-endpoint = <0x2d>;
					};
				};

				port@3 {
					reg = <0x3>;

					endpoint {
						remote-endpoint = <0x2e>;
					};
				};
			};

			vdoa@021e4000 {
				reg = <0x21e4000 0x4000>;
				interrupts = <0x0 0x12 0x4>;
			};

			serial@021e8000 {
				compatible = "fsl,imx6q-uart", "fsl,imx21-uart";
				reg = <0x21e8000 0x4000>;
				interrupts = <0x0 0x1b 0x4>;
				clocks = <0x2 0xa0 0x2 0xa1>;
				clock-names = "ipg", "per";
				dmas = <0x4 0x1b 0x4 0x0 0x4 0x1c 0x4 0x0>;
				dma-names = "rx", "tx";
				status = "okay";
				pinctrl-names = "default";
				pinctrl-0 = <0x2f>;
			};

			serial@021ec000 {
				compatible = "fsl,imx6q-uart", "fsl,imx21-uart";
				reg = <0x21ec000 0x4000>;
				interrupts = <0x0 0x1c 0x4>;
				clocks = <0x2 0xa0 0x2 0xa1>;
				clock-names = "ipg", "per";
				dmas = <0x4 0x1d 0x4 0x0 0x4 0x1e 0x4 0x0>;
				dma-names = "rx", "tx";
				status = "disabled";
			};

			serial@021f0000 {
				compatible = "fsl,imx6q-uart", "fsl,imx21-uart";
				reg = <0x21f0000 0x4000>;
				interrupts = <0x0 0x1d 0x4>;
				clocks = <0x2 0xa0 0x2 0xa1>;
				clock-names = "ipg", "per";
				dmas = <0x4 0x1f 0x4 0x0 0x4 0x20 0x4 0x0>;
				dma-names = "rx", "tx";
				status = "disabled";
			};

			serial@021f4000 {
				compatible = "fsl,imx6q-uart", "fsl,imx21-uart";
				reg = <0x21f4000 0x4000>;
				interrupts = <0x0 0x1e 0x4>;
				clocks = <0x2 0xa0 0x2 0xa1>;
				clock-names = "ipg", "per";
				dmas = <0x4 0x21 0x4 0x0 0x4 0x22 0x4 0x0>;
				dma-names = "rx", "tx";
				status = "disabled";
			};
		};
/*
		ipu@02400000 {
			#address-cells = <0x1>;
			#size-cells = <0x0>;
			compatible = "fsl,imx6q-ipu";
			reg = <0x2400000 0x400000>;
			interrupts = <0x0 0x6 0x4 0x0 0x5 0x4>;
			clocks = <0x2 0x82 0x2 0x83 0x2 0x84>;
			clock-names = "bus", "di0", "di1";
			resets = <0x30 0x2>;

			port@0 {
				reg = <0x0>;
			};

			port@1 {
				reg = <0x1>;
			};

			port@2 {
				#address-cells = <0x1>;
				#size-cells = <0x0>;
				reg = <0x2>;
				linux,phandle = <0x43>;
				phandle = <0x43>;

				endpoint@0 {
				};

				endpoint@1 {
					remote-endpoint = <0x31>;
					linux,phandle = <0x18>;
					phandle = <0x18>;
				};

				endpoint@2 {
					remote-endpoint = <0x32>;
					linux,phandle = <0x2b>;
					phandle = <0x2b>;
				};

				endpoint@3 {
					remote-endpoint = <0x33>;
					linux,phandle = <0xf>;
					phandle = <0xf>;
				};

				endpoint@4 {
					remote-endpoint = <0x34>;
					linux,phandle = <0x14>;
					phandle = <0x14>;
				};
			};

			port@3 {
				#address-cells = <0x1>;
				#size-cells = <0x0>;
				reg = <0x3>;
				linux,phandle = <0x44>;
				phandle = <0x44>;

				endpoint@0 {
				};

				endpoint@1 {
					remote-endpoint = <0x35>;
					linux,phandle = <0x19>;
					phandle = <0x19>;
				};

				endpoint@2 {
					remote-endpoint = <0x36>;
					linux,phandle = <0x2c>;
					phandle = <0x2c>;
				};

				endpoint@3 {
					remote-endpoint = <0x37>;
					linux,phandle = <0x10>;
					phandle = <0x10>;
				};

				endpoint@4 {
					remote-endpoint = <0x38>;
					linux,phandle = <0x15>;
					phandle = <0x15>;
				};
			};
		};
*/
		sram@00900000 {
			compatible = "mmio-sram";
			reg = <0x900000 0x40000>;
			clocks = <0x2 0x8e>;
		};
/*
		sata@02200000 {
			compatible = "fsl,imx6q-ahci";
			reg = <0x2200000 0x4000>;
			interrupts = <0x0 0x27 0x4>;
			clocks = <0x2 0x9a 0x2 0xbb 0x2 0x69>;
			clock-names = "sata", "sata_ref", "ahb";
			status = "okay";
		};
*/
/*
		ipu@02800000 {
			#address-cells = <0x1>;
			#size-cells = <0x0>;
			compatible = "fsl,imx6q-ipu";
			reg = <0x2800000 0x400000>;
			interrupts = <0x0 0x8 0x4 0x0 0x7 0x4>;
			clocks = <0x2 0x85 0x2 0x86 0x2 0x89>;
			clock-names = "bus", "di0", "di1";
			resets = <0x30 0x4>;

			port@0 {
				reg = <0x0>;
			};

			port@1 {
				reg = <0x1>;
			};

			port@2 {
				#address-cells = <0x1>;
				#size-cells = <0x0>;
				reg = <0x2>;
				linux,phandle = <0x45>;
				phandle = <0x45>;

				endpoint@0 {
				};

				endpoint@1 {
					remote-endpoint = <0x39>;
					linux,phandle = <0x1a>;
					phandle = <0x1a>;
				};

				endpoint@2 {
					linux,phandle = <0x2d>;
					phandle = <0x2d>;
				};

				endpoint@3 {
					remote-endpoint = <0x3a>;
					linux,phandle = <0x11>;
					phandle = <0x11>;
				};

				endpoint@4 {
					remote-endpoint = <0x3b>;
					linux,phandle = <0x16>;
					phandle = <0x16>;
				};
			};

			port@3 {
				#address-cells = <0x1>;
				#size-cells = <0x0>;
				reg = <0x3>;
				linux,phandle = <0x46>;
				phandle = <0x46>;

				endpoint@1 {
					remote-endpoint = <0x3c>;
					linux,phandle = <0x1b>;
					phandle = <0x1b>;
				};

				endpoint@2 {
					linux,phandle = <0x2e>;
					phandle = <0x2e>;
				};

				endpoint@3 {
					remote-endpoint = <0x3d>;
					linux,phandle = <0x12>;
					phandle = <0x12>;
				};

				endpoint@4 {
					remote-endpoint = <0x3e>;
					linux,phandle = <0x17>;
					phandle = <0x17>;
				};
			};
		};
*/
	};

	cpus {
		#address-cells = <0x1>;
		#size-cells = <0x0>;

		cpu@0 {
			compatible = "arm,cortex-a9";
			device_type = "cpu";
			reg = <0x0>;
			next-level-cache = <0x3f>;
			operating-points = <0x124f80 0x137478 0xf32a0 0x1312d0 0xd0020 0x1312d0 0xc15c0 0x118c30 0x60ae0 0xee098>;
			fsl,soc-operating-points = <0x124f80 0x137478 0xf32a0 0x1312d0 0xd0020 0x1312d0 0xc15c0 0x11edd8 0x60ae0 0x11edd8>;
			clock-latency = <0xee6c>;
			clocks = <0x2 0x68 0x2 0x6 0x2 0x10 0x2 0x11 0x2 0xaa>;
			clock-names = "arm", "pll2_pfd2_396m", "step", "pll1_sw", "pll1_sys";
			arm-supply = <0x40>;
			pu-supply = <0x41>;
			soc-supply = <0x42>;
		};

		cpu@1 {
			compatible = "arm,cortex-a9";
			device_type = "cpu";
			reg = <0x1>;
			next-level-cache = <0x3f>;
		};
/*
		cpu@2 {
			compatible = "arm,cortex-a9";
			device_type = "cpu";
			reg = <0x2>;
			next-level-cache = <0x3f>;
		};

		cpu@3 {
			compatible = "arm,cortex-a9";
			device_type = "cpu";
			reg = <0x3>;
			next-level-cache = <0x3f>;
		};
*/
	};
/*
	display-subsystem {
		compatible = "fsl,imx-display-subsystem";
		ports = <0x43 0x44 0x45 0x46>;
	};
*/
	regulators {
		compatible = "simple-bus";
		#address-cells = <0x1>;
		#size-cells = <0x0>;

		regulator@0 {
			compatible = "regulator-fixed";
			reg = <0x0>;
			regulator-name = "2P5V";
			regulator-min-microvolt = <0x2625a0>;
			regulator-max-microvolt = <0x2625a0>;
			regulator-always-on;
			linux,phandle = <0x29>;
			phandle = <0x29>;
		};

		regulator@1 {
			compatible = "regulator-fixed";
			reg = <0x1>;
			regulator-name = "3P3V";
			regulator-min-microvolt = <0x325aa0>;
			regulator-max-microvolt = <0x325aa0>;
			regulator-always-on;
			linux,phandle = <0x25>;
			phandle = <0x25>;
		};

		regulator@2 {
			compatible = "regulator-fixed";
			reg = <0x2>;
			regulator-name = "usb_otg_vbus";
			regulator-min-microvolt = <0x4c4b40>;
			regulator-max-microvolt = <0x4c4b40>;
			gpio = <0x5 0x16 0x0>;
			enable-active-high;
			linux,phandle = <0x1e>;
			phandle = <0x1e>;
		};
	};
/*
	gpio-keys {
		compatible = "gpio-keys";
		pinctrl-names = "default";
		pinctrl-0 = <0x47>;

		power {
			label = "Power Button";
			gpios = <0x27 0x3 0x1>;
			linux,code = <0x74>;
			gpio-key,wakeup;
		};

		menu {
			label = "Menu";
			gpios = <0x27 0x1 0x1>;
			linux,code = <0x8b>;
		};

		home {
			label = "Home";
			gpios = <0x27 0x4 0x1>;
			linux,code = <0x66>;
		};

		back {
			label = "Back";
			gpios = <0x27 0x2 0x1>;
			linux,code = <0x9e>;
		};

		volume-up {
			label = "Volume Up";
			gpios = <0x24 0xd 0x1>;
			linux,code = <0x73>;
		};

		volume-down {
			label = "Volume Down";
			gpios = <0x48 0x5 0x1>;
			linux,code = <0x72>;
		};
	};
	sound {
		compatible = "fsl,imx6q-sabrelite-sgtl5000", "fsl,imx-audio-sgtl5000";
		model = "imx6q-sabrelite-sgtl5000";
		ssi-controller = <0x49>;
		audio-codec = <0x4a>;
		audio-routing = "MIC_IN", "Mic Jack", "Mic Jack", "Mic Bias", "Headphone Jack", "HP_OUT";
		mux-int-port = <0x1>;
		mux-ext-port = <0x4>;
	};

	backlight_lcd {
		compatible = "pwm-backlight";
		pwms = <0x4b 0x0 0x4c4b40>;
		brightness-levels = <0x0 0x4 0x8 0x10 0x20 0x40 0x80 0xff>;
		default-brightness-level = <0x7>;
		power-supply = <0x25>;
		status = "okay";
	};

	backlight_lvds {
		compatible = "pwm-backlight";
		pwms = <0x4c 0x0 0x4c4b40>;
		brightness-levels = <0x0 0x4 0x8 0x10 0x20 0x40 0x80 0xff>;
		default-brightness-level = <0x7>;
		power-supply = <0x25>;
		status = "okay";
	};
*/
};
